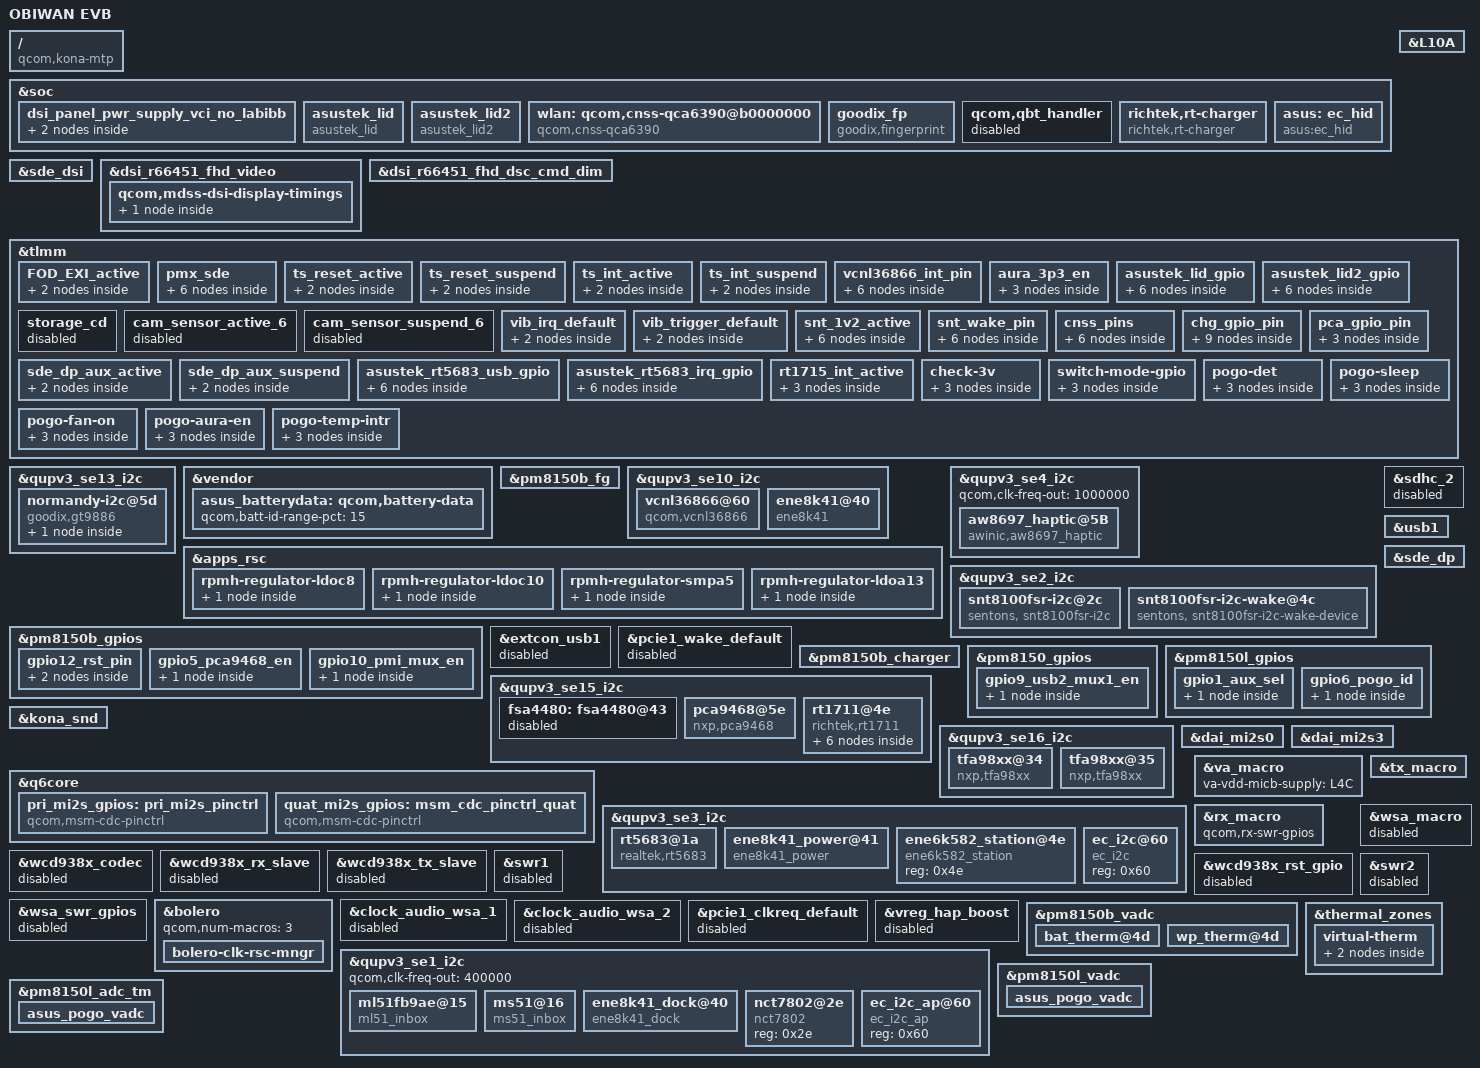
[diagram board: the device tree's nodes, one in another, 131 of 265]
/dts-v1/;
/plugin/;

#include <dt-bindings/clock/qcom,gcc-kona.h>
#include <dt-bindings/clock/qcom,camcc-kona.h>
#include <dt-bindings/clock/qcom,rpmh.h>
#include <dt-bindings/interrupt-controller/arm-gic.h>

#include "kona-mtp.dtsi"
#include "camera/zs661ks-cn-evb-camera-sensor-mtp.dtsi"

#include "dsi-panel-asus-r66451-fhd-dsc-cmd-dim.dtsi"
#include "dsi-panel-asus-r66451-fhd-video.dtsi"

/ {
	model = "OBIWAN EVB";
	compatible = "qcom,kona-mtp", "qcom,kona", "qcom,mtp";
	qcom,board-id = <10 0>;
};

//
// ASUS_BSP Display dtsi overlay +++
// Do not add codes that are not related to display below this
// thank you
//
&soc {
	dsi_panel_pwr_supply_vci_no_labibb: dsi_panel_pwr_supply_vci_no_labibb {
		#address-cells = <1>;
		#size-cells = <0>;

		qcom,panel-supply-entry@0 {
			reg = <0>;
			qcom,supply-name = "vddio";
			qcom,supply-min-voltage = <1800000>;
			qcom,supply-max-voltage = <1800000>;
			qcom,supply-enable-load = <62000>;
			qcom,supply-disable-load = <80>;
			qcom,supply-post-on-sleep = <600>; //600 means 600us
			qcom,supply-pre-off-sleep = <2>;
		};

		qcom,panel-supply-entry@1 {
			reg = <1>;
			qcom,supply-name = "vci";
			qcom,supply-min-voltage = <2960000>;
			qcom,supply-max-voltage = <2960000>;
			qcom,supply-enable-load = <857000>;
			qcom,supply-disable-load = <0>;
			qcom,supply-post-on-sleep = <0>;
			qcom,supply-post-off-sleep = <2>;
		};
	};
};

&sde_dsi {
	/delete-property/ vdd-supply;
	/delete-property/ avdd-supply;

	vci-supply = <&pm8150_l10>;
	qcom,dsi-default-panel = <&dsi_r66451_fhd_video>; // Obiwan EVB does not have TE pin, using video mode panel

	pinctrl-0 = <&sde_dsi_active &sde_te_active &FOD_EXI_active>;
	asus,platform-fod-exi1-gpio = <&tlmm 38 0>;
	asus,platform-fod-exi2-gpio = <&tlmm 39 0>;
};

&dsi_r66451_fhd_video {
	qcom,panel-supply-entries = <&dsi_panel_pwr_supply_vci_no_labibb>;
	qcom,mdss-dsi-bl-pmic-control-type = "bl_ctrl_dcs";
	qcom,mdss-dsi-bl-min-level = <1>;
	qcom,mdss-dsi-bl-max-level = <4095>;
	qcom,mdss-dsi-mode-sel-gpio-state = "single_port";
	qcom,platform-reset-gpio = <&tlmm 75 0>;
	qcom,platform-te-gpio = <&tlmm 66 0>;

	qcom,mdss-dsi-t-clk-post = <0x18>;
	qcom,mdss-dsi-t-clk-pre = <0x1B>;
	qcom,mdss-dsi-display-timings {
		timing@0{
			qcom,mdss-dsi-panel-phy-timings = [00 18 06 06 21 20 06
					06 04 02 04 00 15 16];
			qcom,display-topology = <1 0 1>;
			qcom,default-topology-index = <0>;
		};
	};
};

&dsi_r66451_fhd_dsc_cmd_dim {
	qcom,panel-supply-entries = <&dsi_panel_pwr_supply_vci_no_labibb>;
	qcom,mdss-dsi-bl-pmic-control-type = "bl_ctrl_dcs";
	qcom,mdss-dsi-bl-min-level = <1>;
	qcom,mdss-dsi-bl-max-level = <4095>;
	qcom,mdss-brightness-max-level = <4095>;
	qcom,mdss-dsi-mode-sel-gpio-state = "single_port";
	qcom,platform-te-gpio = <&tlmm 66 0>;
	qcom,platform-reset-gpio = <&tlmm 75 0>;
};

// display regulator vci power supply
&L10A {
	regulator-min-microvolt = <1800000>;
	regulator-max-microvolt = <2960000>;
	qcom,init-voltage = <2960000>;
	//regulator-always-on;
};

// display pinctrl
&tlmm {
	/delete-property/ display_panel_avdd_default;

	FOD_EXI_active: FOD_EXI_active {
		mux {
			pins = "gpio38", "gpio39";
			function = "gpio";
		};
		config {
			pins = "gpio38", "gpio39";
			drive-strength = <8>;   /* 8 mA */
			bias-disable;           /* NO PULL */
			output-low;
		};
	};

	pmx_sde: pmx_sde {
		sde_dsi_active: sde_dsi_active {
			mux {
				pins = "gpio75";
				function = "gpio";
			};

			config {
				pins = "gpio75";
				drive-strength = <8>;   /* 8 mA */
				bias-disable = <0>;   /* no pull */
			};
		};

		sde_dsi_suspend: sde_dsi_suspend {
			mux {
				pins = "gpio75";
				function = "gpio";
			};

			config {
				pins = "gpio75";
				drive-strength = <2>;   /* 2 mA */
				bias-pull-down;         /* PULL DOWN */
			};
		};
	};
};
//
// ASUS_BSP Display dtsi overlay ---
// Do not add codes that are not related to display ABOVE this line
// thank you
//

// ASUS_BSP +++ Jiunhau_Wang [ZS661KS][Touch][RD][Porting] touch mini-porting
 &qupv3_se13_i2c {
	status = "ok";
	normandy-i2c@5d{
		compatible = "goodix,gt9886";
		reg = <0x5d>;
		interrupt-parent = <&tlmm>;
		vtouch-supply = <&pm8150_l10>;
		interrupts = <68 0x2008>;
		panel = <&dsi_r66451_fhd_video &dsi_r66451_fhd_dsc_cmd_dim>;
		pinctrl-names = "pmx_ts_active","pmx_ts_suspend";
		pinctrl-0 = <&ts_int_active &ts_reset_active>;
		pinctrl-1 = <&ts_int_suspend &ts_reset_suspend>;
		goodix,reset-gpio = <&tlmm 69 0x01>;
		goodix,irq-gpio = <&tlmm 68 0x2008>;
		goodix,irq-flags = <2>; /* 1:trigger rising, 2:trigger falling;*/
                goodix,panel-max-id = <10>; //max touch numbers
                goodix,panel-max-x = <1080>; // x
                goodix,panel-max-y = <2340>; // y
                goodix,panel-max-w = <512>; //touch major
                goodix,panel-max-p = <512>; //touch pressure
		goodix,panel-key-map = <158 172 217>; /*KEY_BACK, KEY_HOMEPAGE, KEY_SEARCH*/
		goodix,power-on-delay-us = <300000>; /*300ms*/
		goodix,power-off-delay-us = <5000>;
		/*goodix,swap-axis;*/
		/*goodix,x2x;*/
		/*goodix,y2y;*/
		goodix,pen-enable;
		goodix,key-of-pen = <331 332>;/*BTN_STYLUS, BTN_STYLUS2*/
		sensor0 {
		    normal-cfg = [];
		};
	};
};
// ASUS_BSP --- Jiunhau_Wang [ZS661KS][Touch][RD][Porting] touch mini-porting

&tlmm {
// ASUS_BSP +++ Jiunhau_Wang [ZS661KS][Touch][RD][Porting] touch mini-porting
	ts_reset_active: ts_reset_active {
		mux {
			pins = "gpio69";
			function = "gpio";
		};

		config {
			pins = "gpio69";
			drive-strength = <12>;   /* 12 mA */
			bias-pull-down;
		};
	};

	ts_reset_suspend: ts_reset_suspend {
		mux {
			pins = "gpio69";
			function = "gpio";
		};

		config {
			pins = "gpio69";
			drive-strength = <2>;   /* 2 mA */
			bias-pull-down;
		};
	};

	ts_int_active: ts_int_active {
		mux {
			pins = "gpio68";
			function = "gpio";
		};

		config {
			pins = "gpio68";
			drive-strength = <8>;   /* 8 mA */
			bias-disable = <0>;   /* no pull */
			input-enable;
		};
	};

	ts_int_suspend: ts_int_suspend {
		mux {
			pins = "gpio68";
			function = "gpio";
		};

		config {
			pins = "gpio68";
			drive-strength = <2>;   /* 2 mA */
			bias-disable;
			input-enable;
		};
	};
// ASUS_BSP --- Jiunhau_Wang [ZS661KS][Touch][RD][Porting] touch mini-porting

	// ASUS_BSP +++ ClayWang vcnl36866
	vcnl36866_int_pin {
		vcnl36866_default: vcnl36866_default {
			mux {
				pins = "gpio126";
				function = "gpio";
			};
				config {
				pins = "gpio126";
				bias-pull-up;
				drive-strength = <6>;
			};
		};
			vcnl36866_sleep: vcnl36866_sleep {
			mux {
				pins = "gpio126";
				function = "gpio";
			};
				config {
				pins = "gpio126";
				bias-pull-up;
				drive-strength = <6>;
			};
		};
	};
	// ASUS_BSP --- ClayWang vcnl36866
};

// ASUS_BSP Fuel guage dtsi overlay +++
&vendor {
	asus_batterydata: qcom,battery-data {
		qcom,batt-id-range-pct = <15>;
		#include "fg-gen4-batterydata-5800mah_4p35V.dtsi"
	};
};

&pm8150b_fg {
	status = "ok";
	qcom,battery-data = <&asus_batterydata>;
	qcom,hold-soc-while-full;
	qcom,linearize-soc;
	qcom,five-pin-battery;
	qcom,cl-wt-enable;
	qcom,soc-scale-mode-en;
	/* ESR fast calibration */
	qcom,fg-esr-timer-chg-fast = <0 7>;
	qcom,fg-esr-timer-dischg-fast = <0 7>;
	qcom,fg-esr-timer-chg-slow = <0 96>;
	qcom,fg-esr-timer-dischg-slow = <0 96>;
	qcom,fg-esr-cal-soc-thresh = <26 230>;
	qcom,fg-esr-cal-temp-thresh = <10 40>;
	qcom,fg-cutoff-voltage = <3400>;
	qcom,fg-empty-voltage = <2800>;
	qcom,fg-cutoff-current = <200>;
	qcom,fg-sys-term-current = <(-500)>;
	qcom,fg-force-load-profile;
};
// ASUS_BSP Fuel guage dtsi overlay ---

// ASUS_BSP +++ ClayWang vcnl36866
&qupv3_se10_i2c {
        status = "ok";
            vcnl36866@60 {
			compatible = "qcom,vcnl36866";
			reg = <0x60>;
			pinctrl-names = "alsps_gpio_high","alsps_gpio_low";
			pinctrl-0 = <&vcnl36866_default>;
			pinctrl-1 = <&vcnl36866_sleep>;
			qcom,alsps-gpio = <&tlmm 126 0x0>;
			vcc_psensor-supply = <&pm8150a_l10>;
			
		};
};

&apps_rsc {
	rpmh-regulator-ldoc8 {
		L8C: pm8150a_l8: regulator-pm8150a-l8 {
			regulator-always-on;	/* ASUS BSP Always Enable 1.8V for I2C & Sensors */
		};
	};

	rpmh-regulator-ldoc10 {
		L10C: pm8150a_l10: regulator-pm8150a-l10 {
			regulator-min-microvolt = <3300000>;
			regulator-max-microvolt = <3300000>;
			//regulator-always-on;	/* ASUS BSP Always Enable 1.8V for I2C & Sensors */
		};
	};
};
// ASUS_BSP --- ClayWang vcnl36866

// Aura Sync on phone +++
&qupv3_se10_i2c {
	status = "ok";
	ene8k41@40 {
		compatible = "ene8k41";
		reg = <0x40>;
		ene,aura_3p3_en = <&tlmm 108 0x0>;
		pinctrl-names = "active";
		pinctrl-0 = <&aura_3p3_en>;
	};
};

&tlmm{
	aura_3p3_en {
		aura_3p3_en: aura_3p3_en {
			mux {
				pins = "gpio108";
				function = "gpio";
			};

			config {
				pins = "gpio108";
				drive-strength = <8>;   /* 8 mA */
			};
		};
	};
};

// Aura Sync on phone ---

//ASUS_BSP Steve2_Yang : hall sensor for station +++
&soc {
	asustek_lid {
		status = "ok";
		compatible = "asustek_lid";
		pinctrl-names = "asustek_lid_active", "asustek_lid_suspend";
		pinctrl-0 = <&asustek_lid_active>;
		pinctrl-1 = <&asustek_lid_suspend>;
		gpios = <&tlmm 121 0x1>;
		asustek_lid,wakeup;
	};
};
//ASUS_BSP Steve2_Yang : hall sensor for station ---

//ASUS_BSP Steve2_Yang : hall sensor for bumper +++
&soc {
	/* hall sensor for Bumper */
	asustek_lid2 {
		status = "ok";
		compatible = "asustek_lid2";
		pinctrl-names = "asustek_lid2_active", "asustek_lid2_suspend";
		pinctrl-0 = <&asustek_lid2_active>;
		pinctrl-1 = <&asustek_lid2_suspend>;
		gpios = <&tlmm 113 0x1>;
		asustek_lid2,wakeup;
	};
};
//ASUS_BSP Steve2_Yang : hall sensor for bumper ---

&tlmm {
		//ASUS_BSP Steve2_Yang : Hall Sensor +++
		asustek_lid_gpio {
			asustek_lid_active: asustek_lid_active {
				mux {
					pins = "gpio121";
					function = "gpio";
				};

				config {
					pins = "gpio121";
					drive-strength = <2>;
					bias-pull-up;
				};
			};

			asustek_lid_suspend: asustek_lid_suspend {
				mux {
					pins = "gpio121";
					function = "gpio";
				};

				config {
					pins = "gpio121";
					drive-strength = <2>;
					bias-pull-up;
				};
			};
		};

		asustek_lid2_gpio {
			asustek_lid2_active: asustek_lid2_active {
				mux {
					pins = "gpio113";
					function = "gpio";
				};

				config {
					pins = "gpio113";
					drive-strength = <2>;
					bias-pull-up;
				};
			};

			asustek_lid2_suspend: asustek_lid2_suspend {
				mux {
					pins = "gpio113";
					function = "gpio";
				};

				config {
					pins = "gpio113";
					drive-strength = <2>;
					bias-pull-up;
				};
			};
		};
		//ASUS_BSP Steve2_Yang : Hall Sensor ---
};

//ASUS_BSP: haptic +++

&tlmm {
		storage_cd: storage_cd {
			status = "disabled";
		};
		cam_sensor_active_6: cam_sensor_active_6 {
			status = "disabled";
		};
		cam_sensor_suspend_6: cam_sensor_suspend_6 {
			status = "disabled";
		};

		vib_irq_default: vib_irq_default{
			mux {
				pins = "gpio77";
				function = "gpio";
			};

			config {
				pins = "gpio77";
				drive-strength = <2>;
				bias-pull-up;
				input-enable;
				};
		};

		vib_trigger_default: vib_trigger_default{
			mux {
				pins = "gpio114";
				function = "gpio";
			};

			config {
				pins = "gpio114";
				drive-strength = <2>;
				bias-disable;
				output-low;
			};
		};
};
//ASUS_BSP: haptic ---

//ASUS_BSP: aw haptic +++
&qupv3_se4_i2c {
	status = "ok";
	qcom,clk-freq-out = <1000000>;
	#address-cells = <1>;
	#size-cells = <0>;

	aw8697_haptic@5B {
		compatible = "awinic,aw8697_haptic";
		reg = <0x5B>;
		interrupt-parent = <&tlmm>;
		interrupts = <77 0>; // set type in driver IRQ_TYPE_NONE
		irq-gpio = <&tlmm 77 0>; // set type in driver IRQ_TYPE_NONE
		vib_mode = < 0 >;   /*mode:   RAM mode->0; CONT mode -> 1*/
		vib_f0_pre = < 1500 >; // 150Hz
		vib_f0_cali_percen = < 7 >;
		vib_cont_drv_lev = < 100 >; // 2*1.414*255/6.1
		vib_cont_drv_lvl_ov = < 100 >;
		vib_cont_td = < 0x006c >;
		vib_cont_zc_thr = < 0x0ff1 >;
		vib_cont_num_brk = < 3 >;
		vib_f0_coeff = < 260 >; /*Don't modify it    2.604167*/
		vib_f0_trace_parameter = < 0x05 0x03 0x02 0x0f >;
		vib_bemf_config = < 0x10 0x08 0x03 0xf8 >;
		vib_sw_brake = < 0x2c >;
		vib_tset = < 0x12 >;
		vib_r_spare = < 0x68 >;
		vib_bstdbg = < 0x30 0xeb 0xd4 0 0 0 >;
		pinctrl-names = "default";
		pinctrl-states = "default";
		pinctrl-0 = <&vib_irq_default>;
		status = "okay";
	};
};
//ASUS_BSP: aw haptic ---
// ASUS_BSP Grip +++
&qupv3_se2_i2c {
	status = "ok";
	snt8100fsr-i2c@2c {
		reg = <0x2c>;
		compatible = "sentons, snt8100fsr-i2c";
		grip_gpio12 = <12>;
		
		qcom,snt-host1-gpio = <&tlmm 122 0x0>;
		qcom,snt-trig0-gpio = <&tlmm 112 0x0>;
		qcom,snt-trig1-gpio = <&tlmm 118 0x0>;
		//qcom,snt-trig1-gpio = <&tlmm 26 0x0>;
		qcom,snt-trig2-gpio = <&tlmm 22 0x0>;
		qcom,snt-trig3-gpio = <&tlmm 99 0x0>;
		//snt,gpio_reset = <&tlmm 12 0x0>;
		snt-rst-gpio = <&pm8150b_gpios 12 0x0>;
		pinctrl-names = "gpio12_rst_on", "gpio12_rst_off", "snt_1v2_active", "snt_1v2_close","snt_wake_up","snt_wake_down";
		pinctrl-0 = <&gpio12_rst_on>;
		pinctrl-1 = <&gpio12_rst_off>;
		pinctrl-2 = <&snt_1v2_active>;
		pinctrl-3 = <&snt_1v2_close>;
		pinctrl-4 = <&snt_wake_up>;
		pinctrl-5 = <&snt_wake_down>;
	};
	snt8100fsr-i2c-wake@4c {
		reg = <0x4c>;
		wake-device = <1>;
		compatible = "sentons, snt8100fsr-i2c-wake-device";
		snt,gpio_hostirq = <&tlmm 125 0x0>;
		grip_gpio4 = <1>;
		//pinctrl-names = "grip_clk32";
		//pinctrl-0 = <&clk_out_default>;	
	};
};

&pm8150b_gpios {
	gpio12_rst_pin {
		gpio12_rst_on: gpio12_rst_on {
			pins = "gpio12"; /* GPIO 12 */
			function = "normal"; /* normal output */
			power-source = <0>; /* VIN0 */
			output-high; /* digital output, no invert */
		};
		
		gpio12_rst_off: gpio12_rst_off {
			pins = "gpio12"; 
			function = "normal"; 
			bias-disable;
			output-low; // digital output, no invert 
			power-source = <0>; 
		};
	};
};


&tlmm {
	snt_1v2_active {
		snt_1v2_active: snt_1v2_active {
			mux {
				pins = "gpio50"; //***** should EE help to connect****
				function = "gpio";
			};
				config {
				pins = "gpio50";
				bias-disable;
				drive-strength = <2>;
				output-high;
			};
		};
		snt_1v2_close: snt_1v2_close {
			mux {
				pins = "gpio50";
				function = "gpio";
			};

			config {
				pins = "gpio50";
				bias-disable;
				drive-strength = <2>;
				output-low;
			};
		};
	};
	snt_wake_pin {
		snt_wake_up: snt_wake_up {
			mux {
				pins = "gpio51";
				function = "gpio";
			};
				config {
				pins = "gpio51";
				bias-disable;
				drive-strength = <2>;
				output-high;
			};
		};
		snt_wake_down: snt_wake_down {
			mux {
				pins = "gpio51";
				function = "gpio";
			};

			config {
				pins = "gpio51";
				bias-disable;
				drive-strength = <2>;
				output-low;
			};
		};
	};
};
// ASUS_BSP Grip ---

//ASUS_BSP Wifi+++
&soc {
	wlan: qcom,cnss-qca6390@b0000000 {
		compatible = "qcom,cnss-qca6390";
		status = "okay";
		pinctrl-names = "wlan_en_active", "wlan_en_sleep", "wifi_ant_gpio";
		pinctrl-0 = <&cnss_wlan_en_active>;
		pinctrl-1 = <&cnss_wlan_en_sleep>;
		pinctrl-2 = <&wifi_ant_switch_1 &wifi_ant_switch_2>;
		vdd-3.0-wifi-antenna-supply = <&pm8150_l13>;
		wlan-asus_ant_10 = <&tlmm 10 0>;
		wlan-asus_ant_15 = <&tlmm 15 0>;
		wlan-asus_ant_136 = <&tlmm 136 0>;
		wlan-asus_ant_137 = <&tlmm 137 0>;
	};
};

&apps_rsc {
	rpmh-regulator-smpa5 {
		S5A: pm8150_s5: regulator-pm8150-s5 {
			regulator-min-microvolt = <1900000>;
			regulator-max-microvolt = <2100000>;
			qcom,init-voltage = <1900000>;
		};
	};

	rpmh-regulator-ldoa13 {
		L13A: pm8150_l13: regulator-pm8150-l13 {
			regulator-min-microvolt = <3000000>;
			regulator-max-microvolt = <3000000>;
		};
	};
};

&tlmm {
	cnss_pins {
		wifi_ant_switch_1: wifi_ant_switch_1 {
			mux {
				pins = "gpio10", "gpio15";
				function = "gpio";
			};

			config {
				pins = "gpio10", "gpio15";
				bias-pull-up;
				output-high;
			};
		};

		wifi_ant_switch_2: wifi_ant_switch_2 {
			mux {
				pins = "gpio136", "gpio137";
				function = "gpio";
			};

			config {
				pins = "gpio136", "gpio137";
				bias-pull-up;
				output-high;
			};
		};
	};
};
//ASUS_BSP Wifi---


//ASUS_BSP: no use SDC2 SD card slot 
&sdhc_2 {
	status = "disabled";
};

// ASUS_BSP Charger dtsi overlay +++
&usb1 {
	dpdm-supply = <&usb2_phy1>;
	extcon = <&pm8150b_charger>;
};

&extcon_usb1 {
	status = "disabled";
};

&pcie1_wake_default {
	status = "disabled";
};

&tlmm {
	chg_gpio_pin {
		chg_input_no_default: chg_input_no_default {
			mux {
				pins = "gpio13", "gpio60";
				function = "gpio";
			};

			config {
				pins = "gpio13", "gpio60";
				drive-strength = <2>;
				bias-disable;
				input-enable;
			};
		};

		chg_output_lo_default: chg_output_lo_default {
			mux {
				pins = "gpio11", "gpio71";
				function = "gpio";
			};

			config {
				pins = "gpio11", "gpio71";
				drive-strength = <2>;
				bias-disable;
				output-low;
			};
		};
			
		chg_input_high_default: chg_input_high_default {
			mux {
				pins = "gpio84";
				function = "gpio";
			};

			config {
				pins = "gpio84";
				drive-strength = <2>;
				bias-pull-up;
				input-enable;
			};
		};
	};

// NXP_PCA9468 +++
		pca_gpio_pin {
			pca_input_hi_default: pca_input_hi_default {
				mux {
					pins = "gpio83";
					function = "gpio";
				};

				config {
					pins = "gpio83";
					drive-strength = <2>;
					bias-pull-up;
					input-enable;
				};
			};
		};
// NXP_PCA9468 ---
};

&pm8150b_charger {
	dpdm2-supply = <&usb2_phy1>;//Add for supporting bottom SDP port
	pm8150l_bob-supply = <&pm8150l_bob>;
	
	qcom,fcc-max-ua = <2750000>;
	qcom,chg-term-current-ma = <(-200)>;
	qcom,lpd-disable = <1>;

	BTM_OVP_ACOK = <&tlmm 13 0x0>;
	POGO_OVP_ACOK = <&tlmm 60 0x0>;
	POGO_OTG_EN = <&tlmm 11 0x0>;
	BTM_OTG_EN = <&tlmm 71 0x0>;
	PMI_MUX_EN = <&pm8150b_gpios 10 0x0>;
	USB2_MUX1_EN = <&pm8150_gpios 9 0x0>;
	PCA9468_EN = <&pm8150b_gpios 5 0x0>;
	POGO_TEMP_INT = <&tlmm 84 0x0>;

	/delete-property/qcom,step-charging-enable;
	/delete-property/qcom,sw-jeita-enable;

	pinctrl-names = "chg_gpio_default";
	pinctrl-0 = <&chg_input_no_default &chg_output_lo_default &chg_input_high_default &usb2_mux1_en_default &pca9468_en_default &pmi_mux_en_default>;
	
	panel = <&dsi_r66451_fhd_video &dsi_r66451_fhd_dsc_cmd_dim>;
	qcom,battery-data = <&asus_batterydata>;
};

&pm8150_gpios {
	gpio9_usb2_mux1_en {
		usb2_mux1_en_default: usb2_mux1_en_default {
			pins = "gpio9";
			function = "normal";
			bias-disable;
			output-low;
			power-source = <0>;
		};
	};
};

&pm8150b_gpios {
	gpio5_pca9468_en {
		pca9468_en_default: pca9468_en_default {
			pins = "gpio5";
			function = "normal";
			bias-disable;
			output-low;
			power-source = <0>;
		};
	};
	
	gpio10_pmi_mux_en {
		pmi_mux_en_default: pmi_mux_en_default {
			pins = "gpio10";
			function = "normal";
			bias-disable;
			output-low;
			power-source = <0>;
		};
	};
};
// ASUS_BSP Charger dtsi overlay ---

/* ASUS BSP DisplayPort, add for DisplayPort +++ */
&sde_dp {
	/delete-property/ qcom,dp-aux-switch;
	qcom,dp-gpio-aux-switch;

	qcom,aux-en-gpio = <&tlmm 162 0>;
	qcom,aux-sel-gpio = <&pm8150l_gpios 1 0x0>;

	pinctrl-names = "mdss_dp_active", "mdss_dp_sleep";
	pinctrl-0 = <&sde_dp_aux_active &sde_dp_usbplug_cc_active &aux_sel_default>;
	pinctrl-1 = <&sde_dp_aux_suspend &sde_dp_usbplug_cc_suspend &aux_sel_default>;
};

&pm8150l_gpios {
	gpio1_aux_sel {
		aux_sel_default: aux_sel_default {
			pins = "gpio1";
			function = "normal";
			bias-disable;
			output-low;
			power-source = <0>;
		};
	};
};

&tlmm {
	sde_dp_aux_active: sde_dp_aux_active {
		mux {
			pins = "gpio27";
			function = "gpio";
		};

		config {
			pins = "gpio27";
			bias-disable = <0>; /* no pull */
			drive-strength = <8>;
		};
	};

	sde_dp_aux_suspend: sde_dp_aux_suspend {
		mux {
			pins = "gpio162";
			function = "gpio";
		};

		config {
			pins = "gpio162";
			bias-pull-down;
			drive-strength = <2>;
		};
	};
};

&qupv3_se15_i2c {
	fsa4480: fsa4480@43 {
		status = "disable";
	};
};
/* ASUS BSP DisplayPort, add for DisplayPort --- */

/*    ====================================
 *    overlay for kona-audio-overlay.dtsi - start
 *    ====================================
 */
&kona_snd {
	qcom,model = "kona-mtp-snd-card";
	qcom,msm-mi2s-master = <1>, <1>, <1>, <1>, <1>, <1>;
	qcom,wcn-bt = <1>;
	qcom,ext-disp-audio-rx = <1>;
	qcom,mi2s-audio-intf = <1>;
	qcom,pri-mi2s-gpios = <&pri_mi2s_gpios>;
	qcom,quat-mi2s-gpios = <&quat_mi2s_gpios>;
	qcom,audio-routing =
		"TX DMIC0", "TX MIC BIAS1",
		"TX MIC BIAS1", "Digital Mic0",
		"TX DMIC1", "TX MIC BIAS1",
		"TX MIC BIAS1", "Digital Mic1",
		"TX DMIC2", "TX MIC BIAS1",
		"TX MIC BIAS1", "Digital Mic2",
		"TX DMIC3", "TX MIC BIAS1",
		"TX MIC BIAS1", "Digital Mic3",
		"TX DMIC4", "TX MIC BIAS1",
		"TX MIC BIAS1", "Digital Mic4",
		"TX DMIC5", "TX MIC BIAS1",
		"MIC BIAS4", "Digital Mic5",
		"RX_TX DEC0_INP", "TX DEC0 MUX",
		"RX_TX DEC1_INP", "TX DEC1 MUX",
		"RX_TX DEC2_INP", "TX DEC2 MUX",
		"RX_TX DEC3_INP", "TX DEC3 MUX",
		"VA_AIF1 CAP", "VA_SWR_CLK",
		"VA_AIF2 CAP", "VA_SWR_CLK",
		"VA_AIF3 CAP", "VA_SWR_CLK",
		"VA MIC BIAS", "Digital Mic0",
		"VA MIC BIAS", "Digital Mic1",
		"VA MIC BIAS", "Digital Mic2",
		"VA MIC BIAS", "Digital Mic3",
		"VA MIC BIAS", "Digital Mic4",
		"VA MIC BIAS", "Digital Mic5",
		"VA DMIC0", "VA MIC BIAS",
		"VA DMIC1", "VA MIC BIAS",
		"VA DMIC2", "VA MIC BIAS",
		"VA DMIC3", "VA MIC BIAS",
		"VA DMIC4", "VA MIC BIAS",
		"VA DMIC5", "VA MIC BIAS";
	qcom,cdc-dmic01-gpios = <&cdc_dmic01_gpios>;
	qcom,cdc-dmic23-gpios = <&cdc_dmic23_gpios>;
	qcom,cdc-dmic45-gpios = <&cdc_dmic45_gpios>;
	asoc-codec  = <&stub_codec>, <&bolero>, <&ext_disp_audio_codec>;
	asoc-codec-names = "msm-stub-codec.1", "bolero_codec",
				"msm-ext-disp-audio-codec-rx";
	qcom,wsa-max-devs = <0>;
	qcom,wsa-devs = <0>;
	qcom,codec-max-aux-devs = <0>;
	qcom,codec-aux-devs = <0>;
	qcom,msm_audio_ssr_devs = <&audio_apr>, <&q6core>, <&lpi_tlmm>,
				  <&bolero>;
};

&q6core {
	pri_mi2s_gpios: pri_mi2s_pinctrl {
		compatible = "qcom,msm-cdc-pinctrl";
		pinctrl-names = "aud_active", "aud_sleep";
		pinctrl-0 = <&pri_aux_pcm_clk_active &pri_aux_pcm_din_active &pri_aux_pcm_dout_active &pri_aux_pcm_sync_active>;
		pinctrl-1 = <&pri_aux_pcm_clk_sleep &pri_aux_pcm_din_sleep &pri_aux_pcm_dout_sleep &pri_aux_pcm_sync_sleep>;
	};
};

&qupv3_se16_i2c {        /* i2c for Amp */
	status = "ok";
	tfa98xx@34 {
		compatible = "nxp,tfa98xx";
		reg = <0x34>;
		reset-gpio = <&tlmm 72 0>;
		irq-gpio = <&tlmm 64 0>;
	};
	tfa98xx@35 {
		compatible = "nxp,tfa98xx";
		reg = <0x35>;
		reset-gpio = <&tlmm 73 0>;
		irq-gpio = <&tlmm 63 0>;
	};
};

&dai_mi2s0 {
	qcom,msm-mi2s-rx-lines = <2>;
	qcom,msm-mi2s-tx-lines = <1>;
};

&qupv3_se3_i2c {        /* i2c for Inbox codec RT5683 */
	status = "ok";
        rt5683@1a {
                compatible = "realtek,rt5683";
                reg = <0x1a>;
                pinctrl-names = "asustek_rt5683_usb_gpio_active", "asustek_rt5683_usb_gpio_suspend";
		pinctrl-0 = <&asustek_rt5683_usb_gpio_active>;
		pinctrl-1 = <&asustek_rt5683_usb_gpio_suspend>;
        };
};

&tlmm {
	asustek_rt5683_usb_gpio {
		asustek_rt5683_usb_gpio_active: asustek_rt5683_usb_gpio_active {
		        mux {
			pins = "gpio82";
				function = "gpio";
			};
			config {
				pins = "gpio82";
				drive-strength = <2>;
				bias-pull-up;
			};
		};

		asustek_rt5683_usb_gpio_suspend: asustek_rt5683_usb_gpio_suspend {
			mux {
				pins = "gpio82";
				function = "gpio";
			};
			config {
				pins = "gpio82";
				drive-strength = <2>;
				bias-pull-down;
			};
		};
	};
	asustek_rt5683_irq_gpio {
		asustek_rt5683_irq_gpio_active: asustek_rt5683_irq_gpio_active {
		        mux {
			        pins = "gpio61";
				function = "gpio";
			};
			config {
				pins = "gpio61";
				drive-strength = <2>;
				bias-pull-up;
			};
		};

		asustek_rt5683_irq_gpio_suspend: asustek_rt5683_irq_gpio_suspend {
			mux {
				pins = "gpio61";
				function = "gpio";
			};
			config {
				pins = "gpio61";
				drive-strength = <2>;
				bias-pull-down;
			};
		};
	};
};

&dai_mi2s3 {
	qcom,msm-mi2s-rx-lines = <1>;
	qcom,msm-mi2s-tx-lines = <2>;
};

&q6core {
	quat_mi2s_gpios: msm_cdc_pinctrl_quat {
		compatible = "qcom,msm-cdc-pinctrl";
		pinctrl-names = "aud_active", "aud_sleep";
		pinctrl-0 = <&quat_mi2s_sck_active &quat_mi2s_ws_active
			&quat_mi2s_sd0_active &quat_mi2s_sd1_active>;
		pinctrl-1 = <&quat_mi2s_sck_sleep &quat_mi2s_ws_sleep
			&quat_mi2s_sd0_sleep &quat_mi2s_sd1_sleep>;
		qcom,lpi-gpios;
	};
};

&va_macro {
	va-vdd-micb-supply = <&L4C>;
};

&tx_macro {
	tx-vdd-micb-supply = <&L4C>;
	qcom,tx-vdd-micb-voltage = <1800000 1800000>;
	qcom,tx-vdd-micb-current = <11200>;
	qcom,tx-dmic-sample-rate = <2400000>;
	qcom,tx-swr-gpios;
};

&rx_macro {
	qcom,rx-swr-gpios;
};

&wcd938x_codec {
	status = "disabled";
};

&wcd938x_rx_slave {
	status = "disabled";
};

&wcd938x_tx_slave {
	status = "disabled";
};

&wcd938x_rst_gpio {
	status = "disabled";
};

&wsa_macro {
	status = "disabled";
};

&wsa_swr_gpios {
	status = "disabled";
};

&swr1 {
	status = "disabled";
};

&swr2 {
	status = "disabled";
};

&bolero {
	qcom,num-macros = <3>;
	bolero-clk-rsc-mngr {
		clock-names = "tx_core_clk", "tx_npl_clk", "rx_core_clk", "rx_npl_clk",
			"va_core_clk", "va_npl_clk";
		clocks = <&clock_audio_tx_1 0>, <&clock_audio_tx_2 0>,
			<&clock_audio_rx_1 0>, <&clock_audio_rx_2 0>,
			<&clock_audio_va_1 0>, <&clock_audio_va_2 0>;
	};
};

&clock_audio_wsa_1 {
	status = "disabled";
};

&clock_audio_wsa_2 {
	status = "disabled";
};

/*    ====================================
 *    overlay for kona-audio-overlay.dtsi - end
 *    ====================================
 */

&soc {
	//ASUS_BSP Peter_Yeh fingerprint sensor +++
	goodix_fp {
		compatible = "goodix,fingerprint";
		fp-gpio-irq = <&tlmm 23 0x00>;
		fp-gpio-reset = <&pm8150b_gpios 1 0x0>;
		vcc-supply = <&pm8150a_l11>;
		asus-fp,vcc-voltage=<3150000 3300000>;
		status = "okay";
	};
	//ASUS_BSP Peter_Yeh fingerprint sensor ---
	
	//Disable qcom default FP setting
	qcom,qbt_handler {
		status = "disable";
	};
};

// ASUS_BSP Austin_T : NXP Charger +++
&pcie1_clkreq_default {	//disable qcom soc gpio83 for PCA9468_INT
	status = "disabled";
};

&vreg_hap_boost {	//disable qcom soc gpio83 for PCA9468_INT
	status = "disabled";
};

&qupv3_se15_i2c {
    	status = "ok";
    	pca9468@5e {
        	compatible = "nxp,pca9468";
        	reg = <0x5e>;
					usbpd-phy = <&pm8150b_pdphy>;
			
        	pca9468,irq-gpio = <&tlmm 83 0x0>;
        	pca9468,input-current-limit = <1900000>; /* 1.9A */
        	pca9468,charging-current = <6000000>; /* 6A */
        	pca9468,float-voltage = <4380000>; /* 4.38V */
        	pca9468,input-itopoff = <700000>; /* 700mA */
        	pca9468,charging-itopoff = <1000000>; /* 500mA */
        	pca9468,sense-resistance = <1>; /* 10mOhm */
        	pca9468,switching-frequency = <7>; /* 1160KHz */

        	pinctrl-names = "pca_gpio_default";
        	pinctrl-0 = <&pca_input_hi_default>;
        	
        	panel = <&dsi_r66451_fhd_video &dsi_r66451_fhd_dsc_cmd_dim>;
    	};
};
// ASUS_BSP Austin_T : NXP Charger ---

&pm8150b_vadc {
	bat_therm@4d {
		reg = <ADC_BAT_THERM_PU2>;
		label = "batt_therm";
		qcom,ratiometric;
		qcom,hw-settle-time = <200>;
		qcom,pre-scaling = <1 1>;
	};
	
	wp_therm@4d {
		reg = <ADC_AMUX_THM1_PU2>;
		label = "wp_therm";
		qcom,ratiometric;
		qcom,hw-settle-time = <200>;
		qcom,pre-scaling = <1 1>;
	};
};


&thermal_zones { 	
	virtual-therm {
		polling-delay-passive = <0>;
		polling-delay = <0>;
		thermal-governor = "user_space";
		thermal-sensors = <&pm8150l_adc_tm ADC_AMUX_THM1_PU2>;
		trips {
			active-config0 {
				temperature = <125000>;
				hysteresis = <1000>;
				type = "passive";
			};
		};
	};
};

//ASUS BSP Richtek TypeC PD +++
&qupv3_se15_i2c {
	status = "ok";
	rt1711@4e {
		compatible = "richtek,rt1711";
		reg = <0x4e>;
		rt1711,irq_pin = <&tlmm 175 0x00>;
		rt-dual,supported_modes = <0>; /* 0: dfp/ufp, 1: dfp, 2: ufp */
		rt-tcpc,name = "type_c_port0"; /* tcpc_device's name */
		rt-tcpc,role_def = <4>; /* 0: SNK Only, 1: SRC Only, 2: DRP, 3: Try.SRC, 4: Try.SNK */
		rt-tcpc,rp_level = <0>; /* 0: Default, 1: 1.5, 2: 3.0 */
		rt-tcpc,vconn_supply  = <0>;  /* 0: Never, 1: Always, 2: EMarkOnly, 3: StartOnly */
		rt-tcpc,notifier_supply_num = <1>; /* the number of notifier supply */
		pinctrl-names = "rt1715_int_active";
		pinctrl-0 = <&rt1715_int_active>;
		pd-data {
			pd,vid = <0x29cf>;
			pd,pid = <0x5081>;
			pd,source-cap-ext = <0x171129cf 0x00000000 0x00000102 0x00000000 0x00000000 0x02000000>;
			pd,mfrs = "RichtekTCPC";

			/*
			 *	VSAFE5V = 0, MAX_POWER = 1, CUSTOM = 2,
			 *	MAX_POWER_LV = 0x21, MAX_POWER_LVIC = 0x31
			 *	MAX_POWER_HV = 0x41, MAX_POWER_HVIC = 0x51
			 */
				pd,charging_policy= <0x22>;

			/*
			 * Fixed 5V, 500 mA <0x00019032>
			 * Fixed 5V, 1A <0x00019064>
			 * Fixed 5V, 2A <0x000190c8>
			 * Fixed 5V, 3A <0x0001912c>
			 * Fixed 9V, 500 mA <0x0002d032>
			 * Fixed 9V, 1A <0x0002d064>
			 * Fixed 9V, 2A <0x0002d0c8>
			 * Fixed 9V, 3A <0x0002d12c>
			 * Variable 5-9V, 1A <0x8642d064>
			 * Variable 5-9V, 2A <0x8642d0c8>
			 * Variable 5-9V, 3A <0x8642d12c>
			 * PPS 3V~5.9V, 3A <0xC0761E3C>
			 */
				pd,source-pdo-size = <1>;
				pd,source-pdo-data = <0x00019032>; /* 5V, 500 mA */
				pd,sink-pdo-size = <2>;
				pd,sink-pdo-data = <0x000190c8 0x000190c8> ;   /* 0x0002d0c8 : 9V, 2A<0x04019032 0x04019064> */

			/*
			 * No DP, host + device
			 *	pd,id-vdo-size = <3>;
					pd,id-vdo-data = <0xd00029cf 0x0 0x00010000>;
			 * With DP
			 *	pd,id-vdo-size = <4>;
					pd,id-vdo-data = <0xec0029cf 0x0 0x00010000 0x11000001>;
			 */

				pd,id-vdo-size = <3>;
				pd,id-vdo-data = <0xd00029cf 0x0 0x00010000>;

			bat,nr = <1>;
			pd,country_nr = <0>;

			bat-info0 {
				bat,vid = <0x29cf>;
				bat,pid = <0x1711>;
				bat,mfrs = "bat1";
				bat,design_cap = <3000>;
			};

			//bat-info1 {
			//	bat,vid = <0x8abc>;
			//	bat,pid = <0x5234>;
			//	bat,mfrs = "bat2";
			//	bat,design_cap = <4000>;
			//};

			//country0 {
			//	pd,country_code = <0x5457>;
			//	pd,country_len = <2>; /* max len = 26 */
			//	pd,country_data = <0xff 0xff>;
			//};

			//country1 {
			//	pd,country_code = <0x5553>;
			//	pd,country_len = <3>; /* max len = 26 */
			//	pd,country_data = <0xf1 0xf2 0xf3>;
			//};
		};

		dpm_caps {
			local_dr_power;
			local_dr_data;
			//local_ext_power;
			local_usb_comm;
			//local_usb_suspend;
			//local_high_cap;
			//local_give_back;
			local_no_suspend;
			local_vconn_supply;

			//attemp_discover_cable_dfp;
			attemp_enter_dp_mode;
			//attemp_discover_cable;
			attemp_discover_id;
			/* 0: disable, 1: prefer_snk, 2: prefer_src */
			pr_check = <0>;
			//pr_reject_as_source;
			//pr_reject_as_sink;
			pr_check_gp_source;
			//pr_check_gp_sink;

			/* 0: disable, 1: prefer_ufp, 2: prefer_dfp */
			dr_check = <0>;
			//dr_reject_as_dfp;
			//dr_reject_as_ufp;
		};
		displayport {
			/* connection type = "both", "ufp_d", "dfp_d" */
			1st_connection = "dfp_d";
			2nd_connection = "dfp_d";
			signal,dp_v13;
			//signal,dp_gen2;
			usbr20_not_used;
			typec,receptacle;
			ufp_d {
				//pin_assignment,mode_a;
				//pin_assignment,mode_b;
				//pin_assignment,mode_c;
				//pin_assignment,mode_d;
				//pin_assignment,mode_e;
			};
			dfp_d {
				/* Only support mode C & D */
				//pin_assignment,mode_a;
				//pin_assignment,mode_b;
				pin_assignment,mode_c;
				pin_assignment,mode_d;
				pin_assignment,mode_e;
				pin_assignment,mode_f;
			};
		};
	};
};

&soc {
	richtek,rt-charger {
	    compatible = "richtek,rt-charger";
	    //vconn-supply = <&vconn_5v>;
	};
};
//ASUS BSP Richtek TypeC PD ---

// ASUS_BSP NFC +++
&qupv3_se1_i2c {
	status = "ok";
	qcom,clk-freq-out = <400000>;
};
// ASUS_BSP NFC ---

&tlmm {
	//ASUS BSP Richtek TypeC PD +++
	rt1715_int_active {
		rt1715_int_active: rt1715_int_active {
			mux {
				pins = "gpio175";
				function = "gpio";
			};

			config {
				pins = "gpio175";
				drive-strength = <2>;
				bias-pull-up;
			};
		};
	};
	//ASUS BSP Richtek TypeC PD ---
};

// ASUS_BSP Deeo : Inbox AURA ML51 +++
&qupv3_se1_i2c {
       status = "ok";
       qcom,clk-freq-out = <400000>;
       ml51fb9ae@15 {
               compatible = "ml51_inbox";
               reg = <0x15>;

               nuvoton,aura_3p3_en = <&tlmm 61 0x0>;
               nuvoton,fan_pwr_on = <&tlmm 117 0x0>;
       };

       ms51@16 {
               compatible = "ms51_inbox";
               reg = <0x16>;

               panel = <&dsi_r66451_fhd_video &dsi_r66451_fhd_dsc_cmd_dim>;
               nuvoton,aura_3p3_en = <&tlmm 61 0x0>;
               nuvoton,ms51_on = <&tlmm 117 0x0>;
       };

};
// ASUS_BSP Deeo : Inbox AURA ML51 ---

// ASUS_BSP Deeo : DT ACCY driver +++
&qupv3_se1_i2c {
    status = "ok";
    ene8k41_dock@40 {
        compatible = "ene8k41_dock";
        reg = <0x40>;
        ene8k41,check-3v-gpio =<&tlmm 61 0>;

		pinctrl-names = "default";
		pinctrl-0 = <&check_3v_default>;
    };

    nct7802@2e {
       reg = <0x2e>;
        compatible = "nct7802";
    };
};

&qupv3_se3_i2c {
    ene8k41_power@41 {
		compatible = "ene8k41_power";
		reg = <0x41>;
		ene8k41,switch-mode-gpio = <&tlmm 117 0x0>;

		pinctrl-names = "default";
		pinctrl-0 = <&switch_mode_default>;
	};
};

&tlmm{
	check-3v {
		check_3v_default: check_3v_default{
			mux {
				pins = "gpio61";
				function = "gpio";
			};
			config {
				pins = "gpio61";
				drive-strength = <8>;   /* 8 mA */
				bias-disable = <0>;   /* no pull */
				input-enable;
			};
		};
	};

	switch-mode-gpio {
		switch_mode_default: switch_mode_default{
			mux {
				pins = "gpio117";
				function = "gpio";
			};
			config {
				pins = "gpio117";
				drive-strength = <8>;   /* 8 mA */
				bias-disable = <0>;   /* no pull */
				input-enable;
			};
		};
	};
};
// ASUS_BSP Deeo : DT ACCY driver ---

// ASUS BSP Deeo : Station ACCY driver +++
&qupv3_se3_i2c {
    status = "ok";
    ene6k582_station@4e {
        compatible = "ene6k582_station";	// For Station AuraLight
        reg = <0x4e>;
        };
};

&qupv3_se3_i2c {
    status = "ok";
    ec_i2c@60 {
        compatible = "ec_i2c";		// For Station EC control
        reg = <0x60>;
        };
};

&qupv3_se1_i2c {
	status = "ok";
	ec_i2c_ap@60{
		compatible = "ec_i2c_ap";	// For Station FW update via I2C
		reg = <0x60>;  
	};
};
// ASUS BSP Deeo : Station ACCY driver ---

// ASUS_BSP Deeo : EC_Driver +++
&soc {
	asus:ec_hid {
		status = "ok";
		compatible = "asus:ec_hid";

		dongle,pogo-sleep = <&tlmm 82 0x0>;
		dongle,pogo-det = <&tlmm 145 0x0>;
		//dongle,pogo-fan-on = <&tlmm 117 0x0>;
		//dongle,pogo-aura-en = <&tlmm 61 0x0>;
		//dongle,pogo-temp-intr = <&tlmm 84 0x0>;

		io-channels = <&pm8150l_vadc ADC_GPIO2>;
		io-channel-names ="asus_pogo_vadc";
		qcom,pogo-id-adc_tm = <&pm8150l_adc_tm ADC_GPIO2>;
		qcom.pogo-id-gpio = <&pm8150l_gpios 6 0x0>;

		pinctrl-names = "default";
		pinctrl-0 = <&pogo_id_default &pogo_sleep_default &pogo_det_default>;

		panel = <&dsi_r66451_fhd_video &dsi_r66451_fhd_dsc_cmd_dim>;
	};
};

&tlmm{
	pogo-det {
		pogo_det_default: pogo_det_default {
			mux {
				pins = "gpio145";
				function = "gpio";
			};

			config {
				pins = "gpio145";
				drive-strength = <8>;   /* 8 mA */
				output-low;
				bias-disable;   /* no pull */
			};
		};
	};
	pogo-sleep {
		pogo_sleep_default: pogo_sleep_default{
			mux {
				pins = "gpio82";
				function = "gpio";
			};
			config {
				pins = "gpio82";
				drive-strength = <8>;
				output-low;
				bias-disable;
			};
		};
	};

	pogo-fan-on {
		pogo_fan_on_default: pogo_fan_on_default{
			mux {
				pins = "gpio117";
				function = "gpio";
			};
			config {
				pins = "gpio117";
				drive-strength = <8>;
				output-low;
				bias-disable;
			};
		};
	};

	pogo-aura-en {
		pogo_aura_en_default: pogo_aura_en_default{
			mux {
				pins = "gpio61";
				function = "gpio";
			};
			config {
				pins = "gpio61";
				drive-strength = <8>;
				output-low;
				bias-disable;
			};
		};
	};

	pogo-temp-intr {
		pogo_temp_intr_default: pogo_temp_intr_default{
			mux {
				pins = "gpio84";
				function = "gpio";
			};
			config {
				pins = "gpio84";
				drive-strength = <8>;
				output-low;
				bias-disable;
			};
		};
	};
};

&pm8150l_gpios {
	gpio6_pogo_id {
		pogo_id_default: pogo_id_default {
			pins = "gpio6";
			function = "normal";
			bias-disable;
			power-source = <0>;
		};
	};
};

&pm8150l_vadc {
	asus_pogo_vadc {
		reg = <ADC_GPIO2>;
		label = "asus_pogo_vadc";
		qcom,hw-settle-time = <200>;
		qcom,pre-scaling = <1 1>;
	};
};

&pm8150l_adc_tm {
	io-channels = <&pm8150l_vadc ADC_AMUX_THM1_PU2>,
					<&pm8150l_vadc ADC_AMUX_THM2_PU2>,
					<&pm8150l_vadc ADC_AMUX_THM3_PU2>,
					<&pm8150l_vadc ADC_GPIO2>;
	asus_pogo_vadc {
		reg = <ADC_GPIO2>;
		qcom,hw-settle-time = <200>;
		qcom,scale-type = <0>;
		qcom,kernel-client;
	};
};
// ASUS_BSP Deeo : EC_Driver ---




